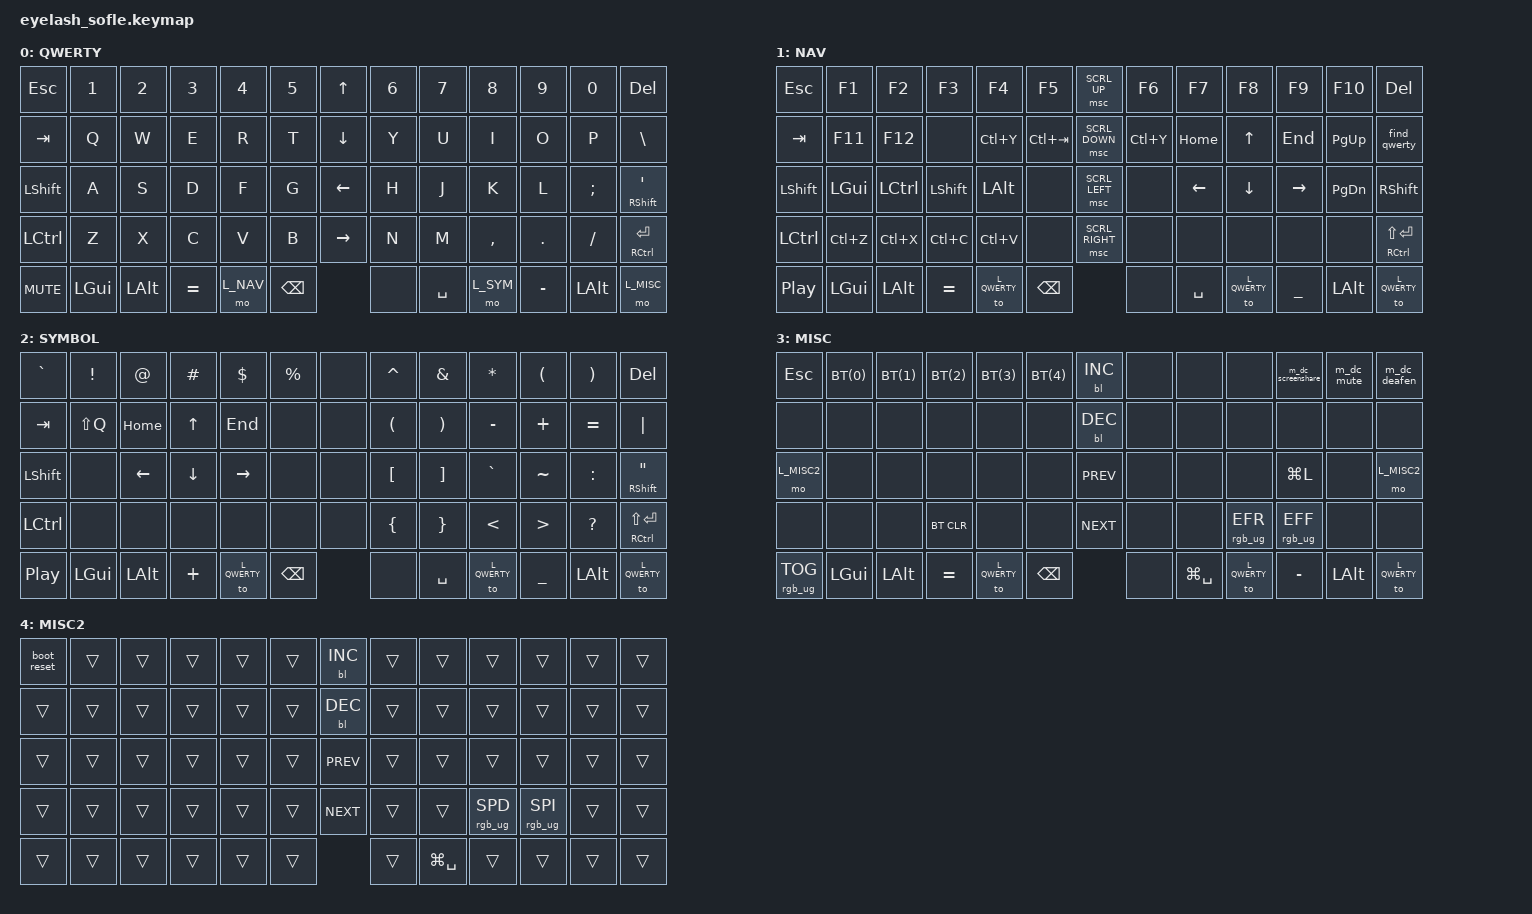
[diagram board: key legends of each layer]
#define ZMK_POINTING_DEFAULT_MOVE_VAL 1200  // 600
#define ZMK_POINTING_DEFAULT_SCRL_VAL 25   // 10

#define L_QWERTY 0
#define L_NAV 1
#define L_SYM 2
#define L_MISC 3
#define L_MISC2 4
#define MO_TOG(layer) &mo_tog layer layer // Macro to apply momentary-layer-on-hold/toggle-layer-on-tap to a specific layer
#define BT(profile) &bt_disc_sel_ ## profile 0 0 // Macro to clear/select bluetooth profiles

#include <input/processors.dtsi>
#include <zephyr/dt-bindings/input/input-event-codes.h>
#include <behaviors.dtsi>
#include <dt-bindings/zmk/bt.h>
#include <dt-bindings/zmk/keys.h>
#include <dt-bindings/zmk/outputs.h>
#include <dt-bindings/zmk/pointing.h>
#include <dt-bindings/zmk/rgb.h>
#include <dt-bindings/zmk/backlight.h>

#include "custom-macros.dtsi"
#include "custom-behaviors.dtsi"


&mmv_input_listener { input-processors = <&zip_xy_scaler 2 1>; };

&msc_input_listener { input-processors = <&zip_scroll_scaler 2 1>; };

&msc {
    acceleration-exponent = <1>;      // 0
    time-to-max-speed-ms = <100>;     // 300
    delay-ms = <0>;                   // 0
};

&mmv {
    time-to-max-speed-ms = <500>;
    acceleration-exponent = <1>;
    trigger-period-ms = <16>;
};

&soft_off { hold-time-ms = <2000>; };

/ {

    keymap {
        compatible = "zmk,keymap";
        
        /* ------------------------------------------------------------------------------------------------------------------------------------------------------------------------------ */
        /* Physical Key Layout Reference
        |  ESC  |  1  |  2  |  3  |  4  |  5  | JOY ↑ |  6  |  7  |  8  |  9  |  0  |  DEL  |
        |  TAB  |  Q  |  W  |  E  |  R  |  T  | JOY ↓ |  Y  |  U  |  I  |  O  |  P  |   \   |
        | LSHFT |  A  |  S  |  D  |  F  |  G  | JOY ← |  H  |  J  |  K  |  L  |  ;  |   :   |
        | LCTRL |  Z  |  X  |  C  |  V  |  B  | JOY → |  N  |  M  |  ,  |  .  |  /  | ENTER |
        
        | KNOB  | SYS | ALT | = | M1 | BACK |JOY_PR| SPC | M2 | - |  M3  | RCTRL |
        */
        QWERTY {
           display-name = "QWERTY";
           bindings = <
           &kp ESC         &kp N1   &kp N2   &kp N3   &kp N4   &kp N5     &kp UP_ARROW        &kp N6   &kp N7   &kp N8      &kp N9    &kp N0      &kp DEL
           &kp TAB         &kp Q    &kp W    &kp E    &kp R    &kp T      &kp DOWN_ARROW      &kp Y    &kp U    &kp I       &kp O     &kp P       &kp BSLH
           &kp LSHFT       &kp A    &kp S    &kp D    &kp F    &kp G      &kp LEFT_ARROW      &kp H    &kp J    &kp K       &kp L     &kp SEMI    &ht RSHIFT SQT
           &kp LCTRL       &kp Z    &kp X    &kp C    &kp V    &kp B      &kp RIGHT_ARROW     &kp N    &kp M    &kp COMMA   &kp DOT   &kp SLASH   &htt RCTRL ENTER
           
           &kp C_MUTE      &kp LEFT_GUI   &kp LALT   &kp EQUAL   &mo L_NAV   &kp BSPC     &none     &kp SPACE   &mo L_SYM   &kp MINUS   &kp LALT   &mo L_MISC
           >;
           sensor-bindings = <&encoder_volume>;
        };
        
        /* ------------------------------------------------------------------------------------------------------------------------------------------------------------------------------ */
        /* Physical Key Layout Reference
        |  ESC  |  1  |  2  |  3  |  4  |  5  | JOY ↑ |  6  |  7  |  8  |  9  |  0  |  DEL  |
        |  TAB  |  Q  |  W  |  E  |  R  |  T  | JOY ↓ |  Y  |  U  |  I  |  O  |  P  |   \   |
        | LSHFT |  A  |  S  |  D  |  F  |  G  | JOY ← |  H  |  J  |  K  |  L  |  ;  |   :   |
        | LCTRL |  Z  |  X  |  C  |  V  |  B  | JOY → |  N  |  M  |  ,  |  .  |  /  | ENTER |
        
        | KNOB  | SYS | ALT | = | M1 | BACK |JOY_PR| SPC | M2 | - |  M3  | RCTRL |
        */
        NAV {
           display-name = "NAV";
           bindings = <
           &kp ESC         &kp F1      &kp F2       &kp F3       &kp F4       &kp F5        &msc SCRL_UP        &kp F6      &kp F7     &kp F8     &kp F9      &kp F10     &kp DEL
           &kp TAB         &kp F11     &kp F12      &none        &kp LC(Y)    &kp LC(TAB)   &msc SCRL_DOWN      &kp LC(Y)   &kp HOME   &kp UP     &kp END     &kp PG_UP   &find_qwerty
           &kp LSHFT       &kp LGUI    &kp LCTRL    &kp LSHIFT   &kp LALT     &none         &msc SCRL_LEFT      &none       &kp LEFT   &kp DOWN   &kp RIGHT   &kp PG_DN   &kp RSHIFT
           &kp LCTRL       &kp LC(Z)   &kp LC(X)    &kp LC(C)    &kp LC(V)    &none         &msc SCRL_RIGHT     &none       &none      &none      &none       &none       &htt RCTRL LS(ENTER)

           &kp C_PLAY_PAUSE    &kp LEFT_GUI   &kp LALT   &kp EQUAL   &to L_QWERTY   &kp BSPC     &none     &kp SPACE   &to L_QWERTY   &kp UNDER   &kp LALT    &to L_QWERTY
           >;
           sensor-bindings = <&encoder_volume>;
        };
        
        /* ------------------------------------------------------------------------------------------------------------------------------------------------------------------------------ */
        /* Physical Key Layout Reference
        |  ESC  |  1  |  2  |  3  |  4  |  5  | JOY ↑ |  6  |  7  |  8  |  9  |  0  |  DEL  |
        |  TAB  |  Q  |  W  |  E  |  R  |  T  | JOY ↓ |  Y  |  U  |  I  |  O  |  P  |   \   |
        | LSHFT |  A  |  S  |  D  |  F  |  G  | JOY ← |  H  |  J  |  K  |  L  |  ;  |   :   |
        | LCTRL |  Z  |  X  |  C  |  V  |  B  | JOY → |  N  |  M  |  ,  |  .  |  /  | ENTER |
        
        | KNOB  | SYS | ALT | = | M1 | BACK |JOY_PR| SPC | M2 | - |  M3  | RCTRL |
        */
        SYMBOL {
            bindings = <
            &kp GRAVE       &kp EXCL      &kp AT     &kp HASH    &kp DLLR     &kp PRCNT     &none     &kp CARET   &kp AMPS   &kp ASTRK   &kp LPAR   &kp RPAR    &kp DEL
            &kp TAB         &kp LS(Q)     &kp HOME   &kp UP      &kp END      &none         &none     &kp LPAR    &kp RPAR   &kp MINUS   &kp PLUS   &kp EQUAL   &kp PIPE
            &kp LSHFT       &none         &kp LEFT   &kp DOWN    &kp RIGHT    &none         &none     &kp LBKT    &kp RBKT   &kp GRAVE   &kp TILDE  &kp COLON   &ht RSHIFT DQT
            &kp LCTRL       &none         &none      &none       &none        &none         &none     &kp LBRC    &kp RBRC   &kp LT      &kp GT     &kp QMARK   &htt RCTRL LS(ENTER)

            &kp C_PLAY_PAUSE   &kp LEFT_GUI   &kp LALT   &kp PLUS   &to L_QWERTY   &kp BSPC     &none    &kp SPACE   &to L_QWERTY   &kp UNDER   &kp LALT   &to L_QWERTY   
            >;
            
            display-name = "SYMBOL";
            sensor-bindings = <&encoder_volume>;
        };
        
        /* ------------------------------------------------------------------------------------------------------------------------------------------------------------------------------ */
        /* Physical Key Layout Reference
        |  ESC  |  1  |  2  |  3  |  4  |  5  | JOY ↑ |  6  |  7  |  8  |  9  |  0  |  DEL  |
        |  TAB  |  Q  |  W  |  E  |  R  |  T  | JOY ↓ |  Y  |  U  |  I  |  O  |  P  |   \   |
        | LSHFT |  A  |  S  |  D  |  F  |  G  | JOY ← |  H  |  J  |  K  |  L  |  ;  |   :   |
        | LCTRL |  Z  |  X  |  C  |  V  |  B  | JOY → |  N  |  M  |  ,  |  .  |  /  | ENTER |
        
        | KNOB  | SYS | ALT | = | M1 | BACK |JOY_PR| SPC | M2 | - |  M3  | RCTRL |
        */
        MISC {
            bindings = <
            &kp ESC       BT(0)   BT(1)   BT(2)        BT(3)   BT(4)     &bl BL_INC     &none   &none   &none             &m_dc_screenshare   &m_dc_mute  &m_dc_deafen
            &none         &none   &none   &none        &none   &none     &bl BL_DEC     &none   &none   &none             &none               &none       &none
            &mo L_MISC2   &none   &none   &none        &none   &none     &kp C_PREV     &none   &none   &none             &kp LG(L)           &none       &mo L_MISC2
            &none         &none   &none   &bt BT_CLR   &none   &none     &kp C_NEXT     &none   &none   &rgb_ug RGB_EFR   &rgb_ug RGB_EFF     &none       &none

            &rgb_ug RGB_TOG   &kp LEFT_GUI   &kp LALT  &kp EQUAL   &to L_QWERTY   &kp BSPC     &none     &kp LG(SPACE)   &to L_QWERTY   &kp MINUS   &kp LALT   &to L_QWERTY
            >;
            
            display-name = "MISC";
            sensor-bindings = <&encoder_rgb_hue>;
        };

        MISC2 {
            bindings = <
            &boot_reset   &trans   &trans   &trans   &trans   &trans     &bl BL_INC      &trans   &trans   &trans           &trans           &trans  &trans
            &trans        &trans   &trans   &trans   &trans   &trans     &bl BL_DEC      &trans   &trans   &trans           &trans           &trans  &trans
            &trans        &trans   &trans   &trans   &trans   &trans     &kp C_PREV      &trans   &trans   &trans           &trans           &trans  &trans
            &trans        &trans   &trans   &trans   &trans   &trans     &kp C_NEXT      &trans   &trans   &rgb_ug RGB_SPD  &rgb_ug RGB_SPI  &trans  &trans

            &trans   &trans   &trans   &trans   &trans   &trans     &trans     &kp LG(SPACE)   &trans   &trans   &trans   &trans
            >;
            
            display-name = "MISC2";
            sensor-bindings = <&encoder_rgb_brightness>;
        };
    };
};
